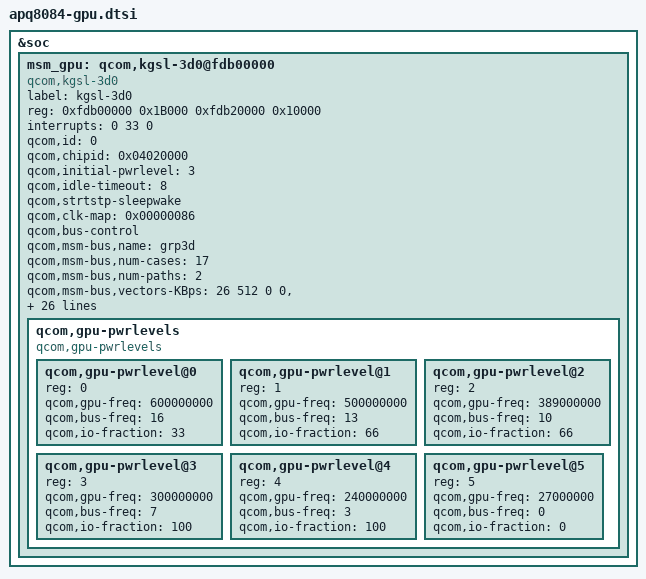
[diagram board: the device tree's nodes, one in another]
/* Copyright (c) 2013-2014, The Linux Foundation. All rights reserved.
 *
 * This program is free software; you can redistribute it and/or modify
 * it under the terms of the GNU General Public License version 2 and
 * only version 2 as published by the Free Software Foundation.
 *
 * This program is distributed in the hope that it will be useful,
 * but WITHOUT ANY WARRANTY; without even the implied warranty of
 * MERCHANTABILITY or FITNESS FOR A PARTICULAR PURPOSE.  See the
 * GNU General Public License for more details.
 */

&soc {
	msm_gpu: qcom,kgsl-3d0@fdb00000 {
		label = "kgsl-3d0";
		compatible = "qcom,kgsl-3d0", "qcom,kgsl-3d";
		reg = <0xfdb00000 0x1B000
		       0xfdb20000 0x10000>;
		reg-names = "kgsl_3d0_reg_memory" , "kgsl_3d0_shader_memory";
		interrupts = <0 33 0>;
		interrupt-names = "kgsl_3d0_irq";
		qcom,id = <0>;

		qcom,chipid = <0x04020000>;

		qcom,initial-pwrlevel = <3>;

		qcom,idle-timeout = <8>; //<HZ/12>
		qcom,strtstp-sleepwake;

		/*
		 * Clocks = KGSL_CLK_CORE | KGSL_CLK_IFACE |
		 * KGSL_CLK_RBBMTIMER
		 */
		qcom,clk-map = <0x00000086>;

		/* Bus Scale Settings */
		qcom,bus-control;
		qcom,msm-bus,name = "grp3d";
		qcom,msm-bus,num-cases = <17>;
		qcom,msm-bus,num-paths = <2>;
		qcom,msm-bus,vectors-KBps =
				<26 512 0 0>, <89 662 0 0>,

				<26 512 0 2400000>,  <89 662 0 3200000>,     // gpu=240 bus=150
				<26 512 0 3200000>,  <89 662 0 3200000>,     // gpu=240 bus=200
				<26 512 0 4915200>,  <89 662 0 3200000>,     // gpu=240 bus=307.2
				<26 512 0 6297600>,  <89 662 0 3200000>,     // gpu=240 bus=393.6

				<26 512 0 3200000>,  <89 662 0 4800000>,     // gpu=300 bus=200
				<26 512 0 4915200>,  <89 662 0 4800000>,     // gpu=300 bus=307.2
				<26 512 0 6297600>,  <89 662 0 4800000>,     // gpu=300 bus=393.6
				<26 512 0 8448000>,  <89 662 0 4800000>,     // gpu=300 bus=528

				<26 512 0 6297600>,  <89 662 0 5600000>,     // gpu=389 bus=393.6
				<26 512 0 8448000>,  <89 662 0 5600000>,     // gpu=389 bus=528
				<26 512 0 10598400>, <89 662 0 5600000>,     // gpu=389 bus=662.4

				<26 512 0 8448000>,  <89 662 0 8000000>,     // gpu=500 bus=528
				<26 512 0 10598400>, <89 662 0 8000000>,     // gpu=500 bus=662.4
				<26 512 0 12748800>, <89 662 0 8000000>,     // gpu=500 bus=796.8

				<26 512 0 10598400>, <89 662 0 9600000>,     // gpu=600 bus=662.4
				<26 512 0 12748800>, <89 662 0 9600000>;     // gpu=600 bus=796.8

		/* GDSC oxili regulators */
		vddcx-supply = <&gdsc_oxili_cx>;
		vdd-supply = <&gdsc_oxili_gx>;

		/* IOMMU Data */
		iommu = <&kgsl_iommu>;

		/* Trace bus */
		coresight-id = <67>;
		coresight-name = "coresight-gfx";
		coresight-nr-inports = <0>;
		coresight-outports = <0>;
		coresight-child-list = <&funnel_in0>;
		coresight-child-ports = <4>;

		/* Power levels */
		qcom,gpu-pwrlevels {
			#address-cells = <1>;
			#size-cells = <0>;

			compatible = "qcom,gpu-pwrlevels";

			qcom,gpu-pwrlevel@0 {
				reg = <0>;
				qcom,gpu-freq = <600000000>;
				qcom,bus-freq = <16>;
				qcom,io-fraction = <33>;
			};

			qcom,gpu-pwrlevel@1 {
				reg = <1>;
				qcom,gpu-freq = <500000000>;
				qcom,bus-freq = <13>;
				qcom,io-fraction = <66>;
			};

			qcom,gpu-pwrlevel@2 {
				reg = <2>;
				qcom,gpu-freq = <389000000>;
				qcom,bus-freq = <10>;
				qcom,io-fraction = <66>;
			};

			qcom,gpu-pwrlevel@3 {
				reg = <3>;
				qcom,gpu-freq = <300000000>;
				qcom,bus-freq = <7>;
				qcom,io-fraction = <100>;
			};

			qcom,gpu-pwrlevel@4 {
				reg = <4>;
				qcom,gpu-freq = <240000000>;
				qcom,bus-freq = <3>;
				qcom,io-fraction = <100>;
			};

			qcom,gpu-pwrlevel@5 {
				reg = <5>;
				qcom,gpu-freq = <27000000>;
				qcom,bus-freq = <0>;
				qcom,io-fraction = <0>;
			};
		};

	};
};

